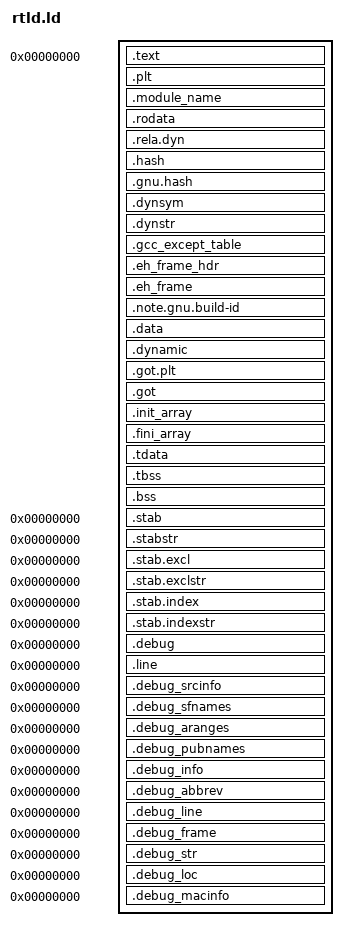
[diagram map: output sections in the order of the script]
OUTPUT_FORMAT(elf64-littleaarch64)
OUTPUT_ARCH(aarch64)
ENTRY(__rtld_entry)

PHDRS
{
  text PT_LOAD FLAGS(5);
  rodata PT_LOAD FLAGS(4);
  data PT_LOAD FLAGS(6);
  bss PT_LOAD FLAGS(6);
  dynamic PT_DYNAMIC;
}

SECTIONS
{
  . = 0;

  /* text sections */
  .text : {
    HIDDEN(__text_start__ = .);
    KEEP (*(.text.crt0))
    *(.text .text.*)
    HIDDEN(__text_end__ = .);
  } :text

  /* Trampoline and stuffs */
  .plt : { *(.plt .plt.*) } :text

  /* Read-only sections */
  . = ALIGN(0x1000);

  /* App name */
  .module_name : { KEEP (*(.rodata.module_name)) } :rodata

  /* Make sure everything is aligned */
  . = ALIGN(8);

  /* App rodata */
  .rodata : {
    *(.rodata .rodata.*)
  } :rodata

  . = ALIGN(8);

  /* All relocations sections */ 
  .rela.dyn       :
    {
      *(.rela.init)
      *(.rela.text .rela.text.* .rela.gnu.linkonce.t.*)
      *(.rela.fini)
      *(.rela.rodata .rela.rodata.* .rela.gnu.linkonce.r.*)
      *(.rela.data .rela.data.* .rela.gnu.linkonce.d.*)
      *(.rela.tdata .rela.tdata.* .rela.gnu.linkonce.td.*)
      *(.rela.tbss .rela.tbss.* .rela.gnu.linkonce.tb.*)
      *(.rela.ctors)
      *(.rela.dtors)
      *(.rela.got)
      *(.rela.bss .rela.bss.* .rela.gnu.linkonce.b.*)
    } :rodata

  /* All the symbols needed for relocation lookup */
  .hash     : { *(.hash) } :rodata
  .gnu.hash : { *(.gnu.hash) } :rodata
  .dynsym   : { *(.dynsym .dynsym.*) } :rodata
  .dynstr   : { *(.dynstr .dynstr.*) } :rodata

  /* All exception handling sections */
  .gcc_except_table : { *(.gcc_except_table .gcc_except_table.*) } :rodata
  .eh_frame_hdr : {
    __eh_frame_hdr_start__ = .;
    *(.eh_frame_hdr)
    __eh_frame_hdr_end__ = .;
  } :rodata
  .eh_frame : { KEEP (*(.eh_frame)) } :rodata

  /* Misc .rodata stuffs (build-id, ect) */
  .note.gnu.build-id : { *(.note.gnu.build-id) } :rodata

  /* DATA sections */
  . = ALIGN(0x1000);

  /* App data */
  .data : {
    *(.data .data.*)
  } :data

  /* The dynamic section as we need it to be stored in the binary */
  .dynamic : {
    PROVIDE(__dynamic_start__ = .);
    *(.dynamic)
  } :data :dynamic

  /* All GOT sections */
	__got_start__ = .;

	.got.plt        : { *(.got.plt)  *(.igot.plt) } :data
	.got            : { *(.got) *(.igot) } :data

	__got_end__ = .;

  /* App init array */
  .init_array ALIGN(8) : {
    KEEP (*(SORT_BY_INIT_PRIORITY(.init_array.*)))
    KEEP (*(.init_array))
  } :data

  /* App fini array */
  .fini_array ALIGN(8) : {
    KEEP (*(SORT_BY_INIT_PRIORITY(.fini_array.*)))
    KEEP (*(.fini_array))
  } :data

  /* Thread Local sections */

  .tdata ALIGN(8) : {
    *(.tdata .tdata.*)
  } :data

  .tbss ALIGN(8) : {
    *(.tbss .tbss.*)
    *(.tcommon)
  } :data

  /* BSS section */

  .bss ALIGN(8) : {
    PROVIDE(__bss_start__ = .);
    *(.bss .bss.*)
    *(COMMON)
    . = ALIGN(8);
    PROVIDE(__bss_end__ = .);
  } :bss

	. = ALIGN(0x1000);
	__argdata__ = .;

  /DISCARD/ : {
    /* No need of the interpreter */
    *(.interp)
  }

  	/* Stabs debugging sections. */
	.stab          0 : { *(.stab) }
	.stabstr       0 : { *(.stabstr) }
	.stab.excl     0 : { *(.stab.excl) }
	.stab.exclstr  0 : { *(.stab.exclstr) }
	.stab.index    0 : { *(.stab.index) }
	.stab.indexstr 0 : { *(.stab.indexstr) }

	/* DWARF debug sections.
	   Symbols in the DWARF debugging sections are relative to the beginning
	   of the section so we begin them at 0. */

	/* DWARF 1 */
	.debug          0 : { *(.debug) }
	.line           0 : { *(.line) }

	/* GNU DWARF 1 extensions */
	.debug_srcinfo  0 : { *(.debug_srcinfo) }
	.debug_sfnames  0 : { *(.debug_sfnames) }

	/* DWARF 1.1 and DWARF 2 */
	.debug_aranges  0 : { *(.debug_aranges) }
	.debug_pubnames 0 : { *(.debug_pubnames) }

	/* DWARF 2 */
	.debug_info     0 : { *(.debug_info) }
	.debug_abbrev   0 : { *(.debug_abbrev) }
	.debug_line     0 : { *(.debug_line) }
	.debug_frame    0 : { *(.debug_frame) }
	.debug_str      0 : { *(.debug_str) }
	.debug_loc      0 : { *(.debug_loc) }
	.debug_macinfo  0 : { *(.debug_macinfo) }
}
